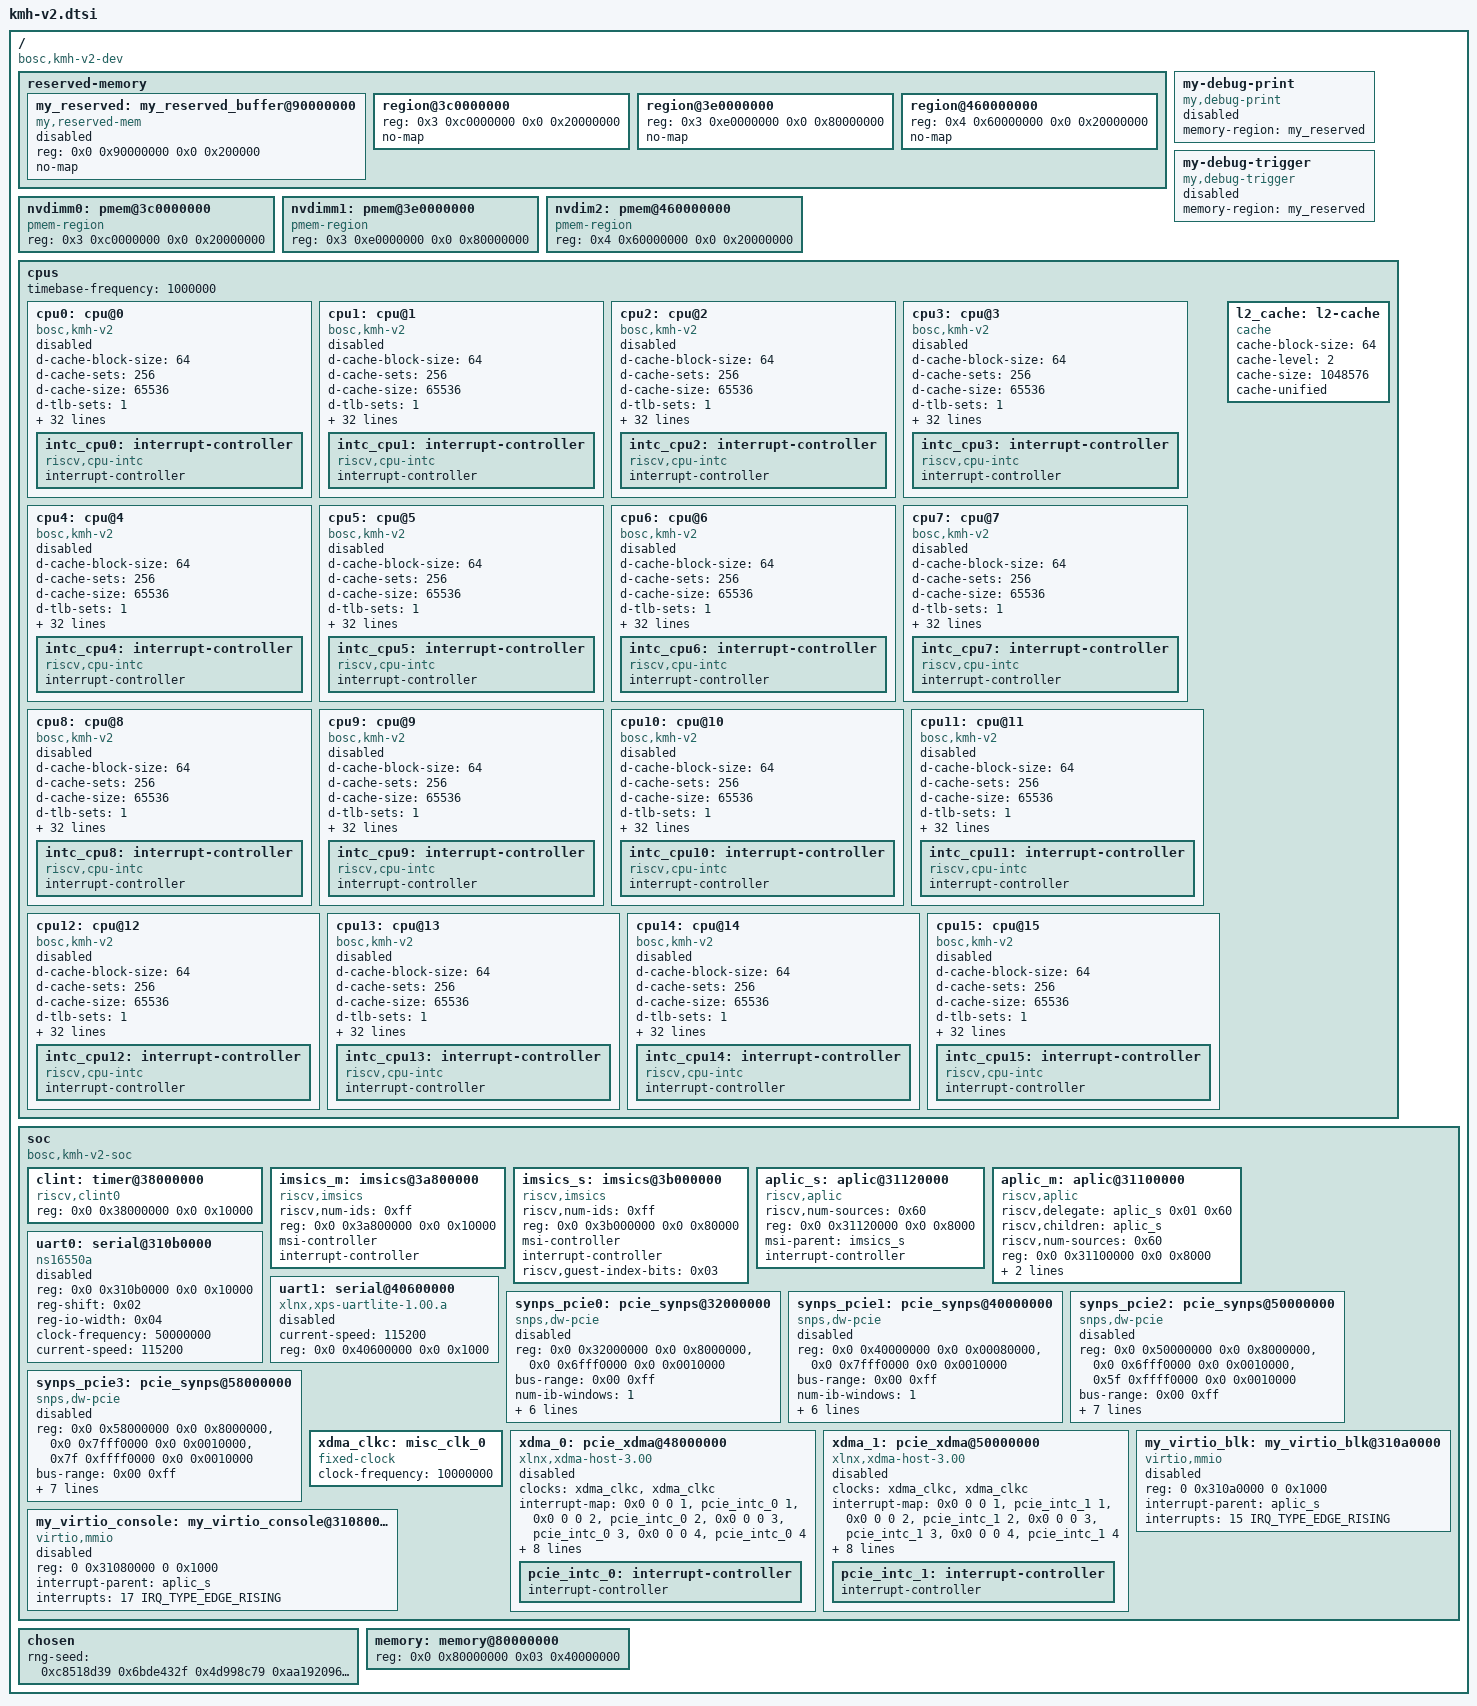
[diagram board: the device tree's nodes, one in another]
// SPDX-License-Identifier: (GPL-2.0 OR MIT)
/* Copyright (c) 2023-2024 BOSC */

/dts-v1/;
#include <dt-bindings/interrupt-controller/irq.h>
/ {
	compatible = "bosc,kmh-v2-dev";
	#address-cells = <2>;
	#size-cells = <2>;

	reserved-memory {
		#address-cells = <2>;
		#size-cells = <2>;
		ranges;

		my_reserved:my_reserved_buffer@90000000 {
			compatible = "my,reserved-mem";
			reg = <0x0 0x90000000 0x0 0x200000>;
			no-map;
			status = "disabled";
		};

		/*
		* NOTE: This region's 'reg' must exactly match the 'reg' in nvdimm_pmem node.
		*       Mismatch will cause pmem driver failure or memory conflict.
		*/
		region@3c0000000 {
		    reg = <0x3 0xc0000000 0x0 0x20000000>;  // 512MB
		    no-map;
		};
		region@3e0000000 {
		    reg = <0x3 0xe0000000 0x0 0x80000000>;  // 2GB
		    no-map;
		};
		region@460000000 {
		    reg = <0x4 0x60000000 0x0 0x20000000>;  // 512MB
		    no-map;
		};
	};

	my-debug-print {
		compatible = "my,debug-print";
		memory-region = <&my_reserved>;
		status = "disabled";
	};
	my-debug-trigger {
		compatible = "my,debug-trigger";
		memory-region = <&my_reserved>;
		status = "disabled";
	};

	nvdimm0: pmem@3c0000000 {
	    compatible = "pmem-region", "nvdimm";
	    reg = <0x3 0xc0000000 0x0 0x20000000>;  // 512MB
	    status = "okay";
	};

	nvdimm1: pmem@3e0000000 {
	    compatible = "pmem-region", "nvdimm";
	    reg = <0x3 0xe0000000 0x0 0x80000000>;  // 2GB
	    status = "okay";
	};

	nvdim2: pmem@460000000 {
	    compatible = "pmem-region", "nvdimm";
	    reg = <0x4 0x60000000 0x0 0x20000000>;  // 512MB
	    status = "okay";
	};

	cpus {
		#address-cells = <1>;
		#size-cells = <0>;
		timebase-frequency = <1000000>; /* 1Mhz */
//		has_hcontext;

		cpu0: cpu@0 {
			compatible = "bosc,kmh-v2", "riscv";
			d-cache-block-size = <64>;
			d-cache-sets = <256>;
			d-cache-size = <65536>;
			d-tlb-sets = <1>;
			d-tlb-size = <48>;
			device_type = "cpu";
			i-cache-block-size = <64>;
			i-cache-sets = <256>;
			i-cache-size = <65536>;
			i-tlb-sets = <1>;
			i-tlb-size = <48>;
			mmu-type = "riscv,sv48";
			reg = <0x0>;
			riscv,isa = "rv64imafdcvh_smaia_smstateen_sscofpmf_sstc_zicntr_zihpm_zicboz_zicbom_svpbmt_sdtrig_smcsrind_sscsrind_svade";
			riscv,isa-base = "rv64i";
			riscv,isa-extensions = "i", "m", "a", "f", "d", "c", "v", "h", "sdtrig", "sha", "shcounterenw", "shgatpa", "shlcofideleg", "shtvala", "shvsatpa", "shvstvala", "shvstvecd", "smaia", "smcsrind", "smdbltrp", "smmpm", "smnpm", "smrnmi", "smstateen", "ss1p13", "ssaia", "ssccptr", "sscofpmf", "sscounterenw", "sscsrind", "ssdbltrp", "ssnpm", "sspm", "ssstateen", "ssstrict", "sstc", "sstvala", "sstvecd", "ssu64xl", "supm", "sv39", "sv48", "svade", "svbare", "svinval", "svnapot", "svpbmt", "za64rs", "zacas", "zawrs", "zba", "zbb", "zbc", "zbkb", "zbkc", "zbkx", "zbs", "zcb", "zcmop", "zfa", "zfh", "zfhmin", "zic64b", "zicbom", "zicbop", "zicboz", "ziccamoa", "ziccif", "zicclsm", "ziccrse", "zicntr", "zicond", "zicsr", "zifencei", "zihintntl", "zihintpause", "zihpm", "zimop", "zkn", "zknd", "zkne", "zknh", "zksed", "zksh", "zkt", "zvbb", "zvfh", "zvfhmin", "zvkt", "zvl128b", "zvl32b", "zvl64b";
			riscv,cbom-block-size = <0x40>;
			riscv,cboz-block-size = <0x40>;
                        status = "disabled";

			next-level-cache = <&l2_cache>;
			tlb-split;
			intc_cpu0: interrupt-controller {
				#interrupt-cells = <1>;
				compatible = "riscv,cpu-intc";
				interrupt-controller;
			};
		};
		cpu1: cpu@1 {
			compatible = "bosc,kmh-v2", "riscv";
			d-cache-block-size = <64>;
			d-cache-sets = <256>;
			d-cache-size = <65536>;
			d-tlb-sets = <1>;
			d-tlb-size = <48>;
			device_type = "cpu";
			i-cache-block-size = <64>;
			i-cache-sets = <256>;
			i-cache-size = <65536>;
			i-tlb-sets = <1>;
			i-tlb-size = <48>;
			mmu-type = "riscv,sv48";
			reg = <0x1>;
			riscv,isa = "rv64imafdcvh_smaia_smstateen_sscofpmf_sstc_zicntr_zihpm_zicboz_zicbom_svpbmt_sdtrig_smcsrind_sscsrind_svade";
			riscv,isa-base = "rv64i";
			riscv,isa-extensions = "i", "m", "a", "f", "d", "c", "v", "h", "sdtrig", "sha", "shcounterenw", "shgatpa", "shlcofideleg", "shtvala", "shvsatpa", "shvstvala", "shvstvecd", "smaia", "smcsrind", "smdbltrp", "smmpm", "smnpm", "smrnmi", "smstateen", "ss1p13", "ssaia", "ssccptr", "sscofpmf", "sscounterenw", "sscsrind", "ssdbltrp", "ssnpm", "sspm", "ssstateen", "ssstrict", "sstc", "sstvala", "sstvecd", "ssu64xl", "supm", "sv39", "sv48", "svade", "svbare", "svinval", "svnapot", "svpbmt", "za64rs", "zacas", "zawrs", "zba", "zbb", "zbc", "zbkb", "zbkc", "zbkx", "zbs", "zcb", "zcmop", "zfa", "zfh", "zfhmin", "zic64b", "zicbom", "zicbop", "zicboz", "ziccamoa", "ziccif", "zicclsm", "ziccrse", "zicntr", "zicond", "zicsr", "zifencei", "zihintntl", "zihintpause", "zihpm", "zimop", "zkn", "zknd", "zkne", "zknh", "zksed", "zksh", "zkt", "zvbb", "zvfh", "zvfhmin", "zvkt", "zvl128b", "zvl32b", "zvl64b";
			riscv,cbom-block-size = <0x40>;
			riscv,cboz-block-size = <0x40>;
                        status = "disabled";

			next-level-cache = <&l2_cache>;
			tlb-split;
			intc_cpu1: interrupt-controller {
				#interrupt-cells = <1>;
				compatible = "riscv,cpu-intc";
				interrupt-controller;
			};
		};
		cpu2: cpu@2 {
			compatible = "bosc,kmh-v2", "riscv";
			d-cache-block-size = <64>;
			d-cache-sets = <256>;
			d-cache-size = <65536>;
			d-tlb-sets = <1>;
			d-tlb-size = <48>;
			device_type = "cpu";
			i-cache-block-size = <64>;
			i-cache-sets = <256>;
			i-cache-size = <65536>;
			i-tlb-sets = <1>;
			i-tlb-size = <48>;
			mmu-type = "riscv,sv48";
			reg = <0x2>;
			riscv,isa = "rv64imafdcvh_smaia_smstateen_sscofpmf_sstc_zicntr_zihpm_zicboz_zicbom_svpbmt_sdtrig_smcsrind_sscsrind_svade";
			riscv,isa-base = "rv64i";
			riscv,isa-extensions = "i", "m", "a", "f", "d", "c", "v", "h", "sdtrig", "sha", "shcounterenw", "shgatpa", "shlcofideleg", "shtvala", "shvsatpa", "shvstvala", "shvstvecd", "smaia", "smcsrind", "smdbltrp", "smmpm", "smnpm", "smrnmi", "smstateen", "ss1p13", "ssaia", "ssccptr", "sscofpmf", "sscounterenw", "sscsrind", "ssdbltrp", "ssnpm", "sspm", "ssstateen", "ssstrict", "sstc", "sstvala", "sstvecd", "ssu64xl", "supm", "sv39", "sv48", "svade", "svbare", "svinval", "svnapot", "svpbmt", "za64rs", "zacas", "zawrs", "zba", "zbb", "zbc", "zbkb", "zbkc", "zbkx", "zbs", "zcb", "zcmop", "zfa", "zfh", "zfhmin", "zic64b", "zicbom", "zicbop", "zicboz", "ziccamoa", "ziccif", "zicclsm", "ziccrse", "zicntr", "zicond", "zicsr", "zifencei", "zihintntl", "zihintpause", "zihpm", "zimop", "zkn", "zknd", "zkne", "zknh", "zksed", "zksh", "zkt", "zvbb", "zvfh", "zvfhmin", "zvkt", "zvl128b", "zvl32b", "zvl64b";
			riscv,cbom-block-size = <0x40>;
			riscv,cboz-block-size = <0x40>;
                        status = "disabled";

			next-level-cache = <&l2_cache>;
			tlb-split;
			intc_cpu2: interrupt-controller {
				#interrupt-cells = <1>;
				compatible = "riscv,cpu-intc";
				interrupt-controller;
			};
		};
		cpu3: cpu@3 {
			compatible = "bosc,kmh-v2", "riscv";
			d-cache-block-size = <64>;
			d-cache-sets = <256>;
			d-cache-size = <65536>;
			d-tlb-sets = <1>;
			d-tlb-size = <48>;
			device_type = "cpu";
			i-cache-block-size = <64>;
			i-cache-sets = <256>;
			i-cache-size = <65536>;
			i-tlb-sets = <1>;
			i-tlb-size = <48>;
			mmu-type = "riscv,sv48";
			reg = <0x3>;
			riscv,isa = "rv64imafdcvh_smaia_smstateen_sscofpmf_sstc_zicntr_zihpm_zicboz_zicbom_svpbmt_sdtrig_smcsrind_sscsrind_svade";
			riscv,isa-base = "rv64i";
			riscv,isa-extensions = "i", "m", "a", "f", "d", "c", "v", "h", "sdtrig", "sha", "shcounterenw", "shgatpa", "shlcofideleg", "shtvala", "shvsatpa", "shvstvala", "shvstvecd", "smaia", "smcsrind", "smdbltrp", "smmpm", "smnpm", "smrnmi", "smstateen", "ss1p13", "ssaia", "ssccptr", "sscofpmf", "sscounterenw", "sscsrind", "ssdbltrp", "ssnpm", "sspm", "ssstateen", "ssstrict", "sstc", "sstvala", "sstvecd", "ssu64xl", "supm", "sv39", "sv48", "svade", "svbare", "svinval", "svnapot", "svpbmt", "za64rs", "zacas", "zawrs", "zba", "zbb", "zbc", "zbkb", "zbkc", "zbkx", "zbs", "zcb", "zcmop", "zfa", "zfh", "zfhmin", "zic64b", "zicbom", "zicbop", "zicboz", "ziccamoa", "ziccif", "zicclsm", "ziccrse", "zicntr", "zicond", "zicsr", "zifencei", "zihintntl", "zihintpause", "zihpm", "zimop", "zkn", "zknd", "zkne", "zknh", "zksed", "zksh", "zkt", "zvbb", "zvfh", "zvfhmin", "zvkt", "zvl128b", "zvl32b", "zvl64b";
			riscv,cbom-block-size = <0x40>;
			riscv,cboz-block-size = <0x40>;
                        status = "disabled";

			next-level-cache = <&l2_cache>;
			tlb-split;
			intc_cpu3: interrupt-controller {
				#interrupt-cells = <1>;
				compatible = "riscv,cpu-intc";
				interrupt-controller;
			};
		};
		cpu4: cpu@4 {
			compatible = "bosc,kmh-v2", "riscv";
			d-cache-block-size = <64>;
			d-cache-sets = <256>;
			d-cache-size = <65536>;
			d-tlb-sets = <1>;
			d-tlb-size = <48>;
			device_type = "cpu";
			i-cache-block-size = <64>;
			i-cache-sets = <256>;
			i-cache-size = <65536>;
			i-tlb-sets = <1>;
			i-tlb-size = <48>;
			mmu-type = "riscv,sv48";
			reg = <0x4>;
			riscv,isa = "rv64imafdcvh_smaia_smstateen_sscofpmf_sstc_zicntr_zihpm_zicboz_zicbom_svpbmt_sdtrig_smcsrind_sscsrind_svade";
			riscv,isa-base = "rv64i";
			riscv,isa-extensions = "i", "m", "a", "f", "d", "c", "v", "h", "sdtrig", "sha", "shcounterenw", "shgatpa", "shlcofideleg", "shtvala", "shvsatpa", "shvstvala", "shvstvecd", "smaia", "smcsrind", "smdbltrp", "smmpm", "smnpm", "smrnmi", "smstateen", "ss1p13", "ssaia", "ssccptr", "sscofpmf", "sscounterenw", "sscsrind", "ssdbltrp", "ssnpm", "sspm", "ssstateen", "ssstrict", "sstc", "sstvala", "sstvecd", "ssu64xl", "supm", "sv39", "sv48", "svade", "svbare", "svinval", "svnapot", "svpbmt", "za64rs", "zacas", "zawrs", "zba", "zbb", "zbc", "zbkb", "zbkc", "zbkx", "zbs", "zcb", "zcmop", "zfa", "zfh", "zfhmin", "zic64b", "zicbom", "zicbop", "zicboz", "ziccamoa", "ziccif", "zicclsm", "ziccrse", "zicntr", "zicond", "zicsr", "zifencei", "zihintntl", "zihintpause", "zihpm", "zimop", "zkn", "zknd", "zkne", "zknh", "zksed", "zksh", "zkt", "zvbb", "zvfh", "zvfhmin", "zvkt", "zvl128b", "zvl32b", "zvl64b";
			riscv,cbom-block-size = <0x40>;
			riscv,cboz-block-size = <0x40>;
                        status = "disabled";

			next-level-cache = <&l2_cache>;
			tlb-split;
			intc_cpu4: interrupt-controller {
				#interrupt-cells = <1>;
				compatible = "riscv,cpu-intc";
				interrupt-controller;
			};
		};
		cpu5: cpu@5 {
			compatible = "bosc,kmh-v2", "riscv";
			d-cache-block-size = <64>;
			d-cache-sets = <256>;
			d-cache-size = <65536>;
			d-tlb-sets = <1>;
			d-tlb-size = <48>;
			device_type = "cpu";
			i-cache-block-size = <64>;
			i-cache-sets = <256>;
			i-cache-size = <65536>;
			i-tlb-sets = <1>;
			i-tlb-size = <48>;
			mmu-type = "riscv,sv48";
			reg = <0x5>;
			riscv,isa = "rv64imafdcvh_smaia_smstateen_sscofpmf_sstc_zicntr_zihpm_zicboz_zicbom_svpbmt_sdtrig_smcsrind_sscsrind_svade";
			riscv,isa-base = "rv64i";
			riscv,isa-extensions = "i", "m", "a", "f", "d", "c", "v", "h", "sdtrig", "sha", "shcounterenw", "shgatpa", "shlcofideleg", "shtvala", "shvsatpa", "shvstvala", "shvstvecd", "smaia", "smcsrind", "smdbltrp", "smmpm", "smnpm", "smrnmi", "smstateen", "ss1p13", "ssaia", "ssccptr", "sscofpmf", "sscounterenw", "sscsrind", "ssdbltrp", "ssnpm", "sspm", "ssstateen", "ssstrict", "sstc", "sstvala", "sstvecd", "ssu64xl", "supm", "sv39", "sv48", "svade", "svbare", "svinval", "svnapot", "svpbmt", "za64rs", "zacas", "zawrs", "zba", "zbb", "zbc", "zbkb", "zbkc", "zbkx", "zbs", "zcb", "zcmop", "zfa", "zfh", "zfhmin", "zic64b", "zicbom", "zicbop", "zicboz", "ziccamoa", "ziccif", "zicclsm", "ziccrse", "zicntr", "zicond", "zicsr", "zifencei", "zihintntl", "zihintpause", "zihpm", "zimop", "zkn", "zknd", "zkne", "zknh", "zksed", "zksh", "zkt", "zvbb", "zvfh", "zvfhmin", "zvkt", "zvl128b", "zvl32b", "zvl64b";
			riscv,cbom-block-size = <0x40>;
			riscv,cboz-block-size = <0x40>;
                        status = "disabled";

			next-level-cache = <&l2_cache>;
			tlb-split;
			intc_cpu5: interrupt-controller {
				#interrupt-cells = <1>;
				compatible = "riscv,cpu-intc";
				interrupt-controller;
			};
		};
		cpu6: cpu@6 {
			compatible = "bosc,kmh-v2", "riscv";
			d-cache-block-size = <64>;
			d-cache-sets = <256>;
			d-cache-size = <65536>;
			d-tlb-sets = <1>;
			d-tlb-size = <48>;
			device_type = "cpu";
			i-cache-block-size = <64>;
			i-cache-sets = <256>;
			i-cache-size = <65536>;
			i-tlb-sets = <1>;
			i-tlb-size = <48>;
			mmu-type = "riscv,sv48";
			reg = <0x6>;
			riscv,isa = "rv64imafdcvh_smaia_smstateen_sscofpmf_sstc_zicntr_zihpm_zicboz_zicbom_svpbmt_sdtrig_smcsrind_sscsrind_svade";
			riscv,isa-base = "rv64i";
			riscv,isa-extensions = "i", "m", "a", "f", "d", "c", "v", "h", "sdtrig", "sha", "shcounterenw", "shgatpa", "shlcofideleg", "shtvala", "shvsatpa", "shvstvala", "shvstvecd", "smaia", "smcsrind", "smdbltrp", "smmpm", "smnpm", "smrnmi", "smstateen", "ss1p13", "ssaia", "ssccptr", "sscofpmf", "sscounterenw", "sscsrind", "ssdbltrp", "ssnpm", "sspm", "ssstateen", "ssstrict", "sstc", "sstvala", "sstvecd", "ssu64xl", "supm", "sv39", "sv48", "svade", "svbare", "svinval", "svnapot", "svpbmt", "za64rs", "zacas", "zawrs", "zba", "zbb", "zbc", "zbkb", "zbkc", "zbkx", "zbs", "zcb", "zcmop", "zfa", "zfh", "zfhmin", "zic64b", "zicbom", "zicbop", "zicboz", "ziccamoa", "ziccif", "zicclsm", "ziccrse", "zicntr", "zicond", "zicsr", "zifencei", "zihintntl", "zihintpause", "zihpm", "zimop", "zkn", "zknd", "zkne", "zknh", "zksed", "zksh", "zkt", "zvbb", "zvfh", "zvfhmin", "zvkt", "zvl128b", "zvl32b", "zvl64b";
			riscv,cbom-block-size = <0x40>;
			riscv,cboz-block-size = <0x40>;
                        status = "disabled";

			next-level-cache = <&l2_cache>;
			tlb-split;
			intc_cpu6: interrupt-controller {
				#interrupt-cells = <1>;
				compatible = "riscv,cpu-intc";
				interrupt-controller;
			};
		};
		cpu7: cpu@7 {
			compatible = "bosc,kmh-v2", "riscv";
			d-cache-block-size = <64>;
			d-cache-sets = <256>;
			d-cache-size = <65536>;
			d-tlb-sets = <1>;
			d-tlb-size = <48>;
			device_type = "cpu";
			i-cache-block-size = <64>;
			i-cache-sets = <256>;
			i-cache-size = <65536>;
			i-tlb-sets = <1>;
			i-tlb-size = <48>;
			mmu-type = "riscv,sv48";
			reg = <0x7>;
			riscv,isa = "rv64imafdcvh_smaia_smstateen_sscofpmf_sstc_zicntr_zihpm_zicboz_zicbom_svpbmt_sdtrig_smcsrind_sscsrind_svade";
			riscv,isa-base = "rv64i";
			riscv,isa-extensions = "i", "m", "a", "f", "d", "c", "v", "h", "sdtrig", "sha", "shcounterenw", "shgatpa", "shlcofideleg", "shtvala", "shvsatpa", "shvstvala", "shvstvecd", "smaia", "smcsrind", "smdbltrp", "smmpm", "smnpm", "smrnmi", "smstateen", "ss1p13", "ssaia", "ssccptr", "sscofpmf", "sscounterenw", "sscsrind", "ssdbltrp", "ssnpm", "sspm", "ssstateen", "ssstrict", "sstc", "sstvala", "sstvecd", "ssu64xl", "supm", "sv39", "sv48", "svade", "svbare", "svinval", "svnapot", "svpbmt", "za64rs", "zacas", "zawrs", "zba", "zbb", "zbc", "zbkb", "zbkc", "zbkx", "zbs", "zcb", "zcmop", "zfa", "zfh", "zfhmin", "zic64b", "zicbom", "zicbop", "zicboz", "ziccamoa", "ziccif", "zicclsm", "ziccrse", "zicntr", "zicond", "zicsr", "zifencei", "zihintntl", "zihintpause", "zihpm", "zimop", "zkn", "zknd", "zkne", "zknh", "zksed", "zksh", "zkt", "zvbb", "zvfh", "zvfhmin", "zvkt", "zvl128b", "zvl32b", "zvl64b";
			riscv,cbom-block-size = <0x40>;
			riscv,cboz-block-size = <0x40>;
                        status = "disabled";

			next-level-cache = <&l2_cache>;
			tlb-split;
			intc_cpu7: interrupt-controller {
				#interrupt-cells = <1>;
				compatible = "riscv,cpu-intc";
				interrupt-controller;
			};
		};
		cpu8: cpu@8 {
			compatible = "bosc,kmh-v2", "riscv";
			d-cache-block-size = <64>;
			d-cache-sets = <256>;
			d-cache-size = <65536>;
			d-tlb-sets = <1>;
			d-tlb-size = <48>;
			device_type = "cpu";
			i-cache-block-size = <64>;
			i-cache-sets = <256>;
			i-cache-size = <65536>;
			i-tlb-sets = <1>;
			i-tlb-size = <48>;
			mmu-type = "riscv,sv48";
			reg = <0x8>;
			riscv,isa = "rv64imafdcvh_smaia_smstateen_sscofpmf_sstc_zicntr_zihpm_zicboz_zicbom_svpbmt_sdtrig_smcsrind_sscsrind_svade";
			riscv,isa-base = "rv64i";
			riscv,isa-extensions = "i", "m", "a", "f", "d", "c", "v", "h", "sdtrig", "sha", "shcounterenw", "shgatpa", "shlcofideleg", "shtvala", "shvsatpa", "shvstvala", "shvstvecd", "smaia", "smcsrind", "smdbltrp", "smmpm", "smnpm", "smrnmi", "smstateen", "ss1p13", "ssaia", "ssccptr", "sscofpmf", "sscounterenw", "sscsrind", "ssdbltrp", "ssnpm", "sspm", "ssstateen", "ssstrict", "sstc", "sstvala", "sstvecd", "ssu64xl", "supm", "sv39", "sv48", "svade", "svbare", "svinval", "svnapot", "svpbmt", "za64rs", "zacas", "zawrs", "zba", "zbb", "zbc", "zbkb", "zbkc", "zbkx", "zbs", "zcb", "zcmop", "zfa", "zfh", "zfhmin", "zic64b", "zicbom", "zicbop", "zicboz", "ziccamoa", "ziccif", "zicclsm", "ziccrse", "zicntr", "zicond", "zicsr", "zifencei", "zihintntl", "zihintpause", "zihpm", "zimop", "zkn", "zknd", "zkne", "zknh", "zksed", "zksh", "zkt", "zvbb", "zvfh", "zvfhmin", "zvkt", "zvl128b", "zvl32b", "zvl64b";
			riscv,cbom-block-size = <0x40>;
			riscv,cboz-block-size = <0x40>;
                        status = "disabled";

			next-level-cache = <&l2_cache>;
			tlb-split;
			intc_cpu8: interrupt-controller {
				#interrupt-cells = <1>;
				compatible = "riscv,cpu-intc";
				interrupt-controller;
			};
		};
		cpu9: cpu@9 {
			compatible = "bosc,kmh-v2", "riscv";
			d-cache-block-size = <64>;
			d-cache-sets = <256>;
			d-cache-size = <65536>;
			d-tlb-sets = <1>;
			d-tlb-size = <48>;
			device_type = "cpu";
			i-cache-block-size = <64>;
			i-cache-sets = <256>;
			i-cache-size = <65536>;
			i-tlb-sets = <1>;
			i-tlb-size = <48>;
			mmu-type = "riscv,sv48";
			reg = <0x9>;
			riscv,isa = "rv64imafdcvh_smaia_smstateen_sscofpmf_sstc_zicntr_zihpm_zicboz_zicbom_svpbmt_sdtrig_smcsrind_sscsrind_svade";
			riscv,isa-base = "rv64i";
			riscv,isa-extensions = "i", "m", "a", "f", "d", "c", "v", "h", "sdtrig", "sha", "shcounterenw", "shgatpa", "shlcofideleg", "shtvala", "shvsatpa", "shvstvala", "shvstvecd", "smaia", "smcsrind", "smdbltrp", "smmpm", "smnpm", "smrnmi", "smstateen", "ss1p13", "ssaia", "ssccptr", "sscofpmf", "sscounterenw", "sscsrind", "ssdbltrp", "ssnpm", "sspm", "ssstateen", "ssstrict", "sstc", "sstvala", "sstvecd", "ssu64xl", "supm", "sv39", "sv48", "svade", "svbare", "svinval", "svnapot", "svpbmt", "za64rs", "zacas", "zawrs", "zba", "zbb", "zbc", "zbkb", "zbkc", "zbkx", "zbs", "zcb", "zcmop", "zfa", "zfh", "zfhmin", "zic64b", "zicbom", "zicbop", "zicboz", "ziccamoa", "ziccif", "zicclsm", "ziccrse", "zicntr", "zicond", "zicsr", "zifencei", "zihintntl", "zihintpause", "zihpm", "zimop", "zkn", "zknd", "zkne", "zknh", "zksed", "zksh", "zkt", "zvbb", "zvfh", "zvfhmin", "zvkt", "zvl128b", "zvl32b", "zvl64b";
			riscv,cbom-block-size = <0x40>;
			riscv,cboz-block-size = <0x40>;
                        status = "disabled";

			next-level-cache = <&l2_cache>;
			tlb-split;
			intc_cpu9: interrupt-controller {
				#interrupt-cells = <1>;
				compatible = "riscv,cpu-intc";
				interrupt-controller;
			};
		};
		cpu10: cpu@10 {
			compatible = "bosc,kmh-v2", "riscv";
			d-cache-block-size = <64>;
			d-cache-sets = <256>;
			d-cache-size = <65536>;
			d-tlb-sets = <1>;
			d-tlb-size = <48>;
			device_type = "cpu";
			i-cache-block-size = <64>;
			i-cache-sets = <256>;
			i-cache-size = <65536>;
			i-tlb-sets = <1>;
			i-tlb-size = <48>;
			mmu-type = "riscv,sv48";
			reg = <0xa>;
			riscv,isa = "rv64imafdcvh_smaia_smstateen_sscofpmf_sstc_zicntr_zihpm_zicboz_zicbom_svpbmt_sdtrig_smcsrind_sscsrind_svade";
			riscv,isa-base = "rv64i";
			riscv,isa-extensions = "i", "m", "a", "f", "d", "c", "v", "h", "sdtrig", "sha", "shcounterenw", "shgatpa", "shlcofideleg", "shtvala", "shvsatpa", "shvstvala", "shvstvecd", "smaia", "smcsrind", "smdbltrp", "smmpm", "smnpm", "smrnmi", "smstateen", "ss1p13", "ssaia", "ssccptr", "sscofpmf", "sscounterenw", "sscsrind", "ssdbltrp", "ssnpm", "sspm", "ssstateen", "ssstrict", "sstc", "sstvala", "sstvecd", "ssu64xl", "supm", "sv39", "sv48", "svade", "svbare", "svinval", "svnapot", "svpbmt", "za64rs", "zacas", "zawrs", "zba", "zbb", "zbc", "zbkb", "zbkc", "zbkx", "zbs", "zcb", "zcmop", "zfa", "zfh", "zfhmin", "zic64b", "zicbom", "zicbop", "zicboz", "ziccamoa", "ziccif", "zicclsm", "ziccrse", "zicntr", "zicond", "zicsr", "zifencei", "zihintntl", "zihintpause", "zihpm", "zimop", "zkn", "zknd", "zkne", "zknh", "zksed", "zksh", "zkt", "zvbb", "zvfh", "zvfhmin", "zvkt", "zvl128b", "zvl32b", "zvl64b";
			riscv,cbom-block-size = <0x40>;
			riscv,cboz-block-size = <0x40>;
                        status = "disabled";

			next-level-cache = <&l2_cache>;
			tlb-split;
			intc_cpu10: interrupt-controller {
				#interrupt-cells = <1>;
				compatible = "riscv,cpu-intc";
				interrupt-controller;
			};
		};
		cpu11: cpu@11 {
			compatible = "bosc,kmh-v2", "riscv";
			d-cache-block-size = <64>;
			d-cache-sets = <256>;
			d-cache-size = <65536>;
			d-tlb-sets = <1>;
			d-tlb-size = <48>;
			device_type = "cpu";
			i-cache-block-size = <64>;
			i-cache-sets = <256>;
			i-cache-size = <65536>;
			i-tlb-sets = <1>;
			i-tlb-size = <48>;
			mmu-type = "riscv,sv48";
			reg = <0xb>;
			riscv,isa = "rv64imafdcvh_smaia_smstateen_sscofpmf_sstc_zicntr_zihpm_zicboz_zicbom_svpbmt_sdtrig_smcsrind_sscsrind_svade";
			riscv,isa-base = "rv64i";
			riscv,isa-extensions = "i", "m", "a", "f", "d", "c", "v", "h", "sdtrig", "sha", "shcounterenw", "shgatpa", "shlcofideleg", "shtvala", "shvsatpa", "shvstvala", "shvstvecd", "smaia", "smcsrind", "smdbltrp", "smmpm", "smnpm", "smrnmi", "smstateen", "ss1p13", "ssaia", "ssccptr", "sscofpmf", "sscounterenw", "sscsrind", "ssdbltrp", "ssnpm", "sspm", "ssstateen", "ssstrict", "sstc", "sstvala", "sstvecd", "ssu64xl", "supm", "sv39", "sv48", "svade", "svbare", "svinval", "svnapot", "svpbmt", "za64rs", "zacas", "zawrs", "zba", "zbb", "zbc", "zbkb", "zbkc", "zbkx", "zbs", "zcb", "zcmop", "zfa", "zfh", "zfhmin", "zic64b", "zicbom", "zicbop", "zicboz", "ziccamoa", "ziccif", "zicclsm", "ziccrse", "zicntr", "zicond", "zicsr", "zifencei", "zihintntl", "zihintpause", "zihpm", "zimop", "zkn", "zknd", "zkne", "zknh", "zksed", "zksh", "zkt", "zvbb", "zvfh", "zvfhmin", "zvkt", "zvl128b", "zvl32b", "zvl64b";
			riscv,cbom-block-size = <0x40>;
			riscv,cboz-block-size = <0x40>;
                        status = "disabled";

			next-level-cache = <&l2_cache>;
			tlb-split;
			intc_cpu11: interrupt-controller {
				#interrupt-cells = <1>;
				compatible = "riscv,cpu-intc";
				interrupt-controller;
			};
		};
		cpu12: cpu@12 {
			compatible = "bosc,kmh-v2", "riscv";
			d-cache-block-size = <64>;
			d-cache-sets = <256>;
			d-cache-size = <65536>;
			d-tlb-sets = <1>;
			d-tlb-size = <48>;
			device_type = "cpu";
			i-cache-block-size = <64>;
			i-cache-sets = <256>;
			i-cache-size = <65536>;
			i-tlb-sets = <1>;
			i-tlb-size = <48>;
			mmu-type = "riscv,sv48";
			reg = <0xc>;
			riscv,isa = "rv64imafdcvh_smaia_smstateen_sscofpmf_sstc_zicntr_zihpm_zicboz_zicbom_svpbmt_sdtrig_smcsrind_sscsrind_svade";
			riscv,isa-base = "rv64i";
			riscv,isa-extensions = "i", "m", "a", "f", "d", "c", "v", "h", "sdtrig", "sha", "shcounterenw", "shgatpa", "shlcofideleg", "shtvala", "shvsatpa", "shvstvala", "shvstvecd", "smaia", "smcsrind", "smdbltrp", "smmpm", "smnpm", "smrnmi", "smstateen", "ss1p13", "ssaia", "ssccptr", "sscofpmf", "sscounterenw", "sscsrind", "ssdbltrp", "ssnpm", "sspm", "ssstateen", "ssstrict", "sstc", "sstvala", "sstvecd", "ssu64xl", "supm", "sv39", "sv48", "svade", "svbare", "svinval", "svnapot", "svpbmt", "za64rs", "zacas", "zawrs", "zba", "zbb", "zbc", "zbkb", "zbkc", "zbkx", "zbs", "zcb", "zcmop", "zfa", "zfh", "zfhmin", "zic64b", "zicbom", "zicbop", "zicboz", "ziccamoa", "ziccif", "zicclsm", "ziccrse", "zicntr", "zicond", "zicsr", "zifencei", "zihintntl", "zihintpause", "zihpm", "zimop", "zkn", "zknd", "zkne", "zknh", "zksed", "zksh", "zkt", "zvbb", "zvfh", "zvfhmin", "zvkt", "zvl128b", "zvl32b", "zvl64b";
			riscv,cbom-block-size = <0x40>;
			riscv,cboz-block-size = <0x40>;
                        status = "disabled";

			next-level-cache = <&l2_cache>;
			tlb-split;
			intc_cpu12: interrupt-controller {
				#interrupt-cells = <1>;
				compatible = "riscv,cpu-intc";
				interrupt-controller;
			};
		};
		cpu13: cpu@13 {
			compatible = "bosc,kmh-v2", "riscv";
			d-cache-block-size = <64>;
			d-cache-sets = <256>;
			d-cache-size = <65536>;
			d-tlb-sets = <1>;
			d-tlb-size = <48>;
			device_type = "cpu";
			i-cache-block-size = <64>;
			i-cache-sets = <256>;
			i-cache-size = <65536>;
			i-tlb-sets = <1>;
			i-tlb-size = <48>;
			mmu-type = "riscv,sv48";
			reg = <0xd>;
			riscv,isa = "rv64imafdcvh_smaia_smstateen_sscofpmf_sstc_zicntr_zihpm_zicboz_zicbom_svpbmt_sdtrig_smcsrind_sscsrind_svade";
			riscv,isa-base = "rv64i";
			riscv,isa-extensions = "i", "m", "a", "f", "d", "c", "v", "h", "sdtrig", "sha", "shcounterenw", "shgatpa", "shlcofideleg", "shtvala", "shvsatpa", "shvstvala", "shvstvecd", "smaia", "smcsrind", "smdbltrp", "smmpm", "smnpm", "smrnmi", "smstateen", "ss1p13", "ssaia", "ssccptr", "sscofpmf", "sscounterenw", "sscsrind", "ssdbltrp", "ssnpm", "sspm", "ssstateen", "ssstrict", "sstc", "sstvala", "sstvecd", "ssu64xl", "supm", "sv39", "sv48", "svade", "svbare", "svinval", "svnapot", "svpbmt", "za64rs", "zacas", "zawrs", "zba", "zbb", "zbc", "zbkb", "zbkc", "zbkx", "zbs", "zcb", "zcmop", "zfa", "zfh", "zfhmin", "zic64b", "zicbom", "zicbop", "zicboz", "ziccamoa", "ziccif", "zicclsm", "ziccrse", "zicntr", "zicond", "zicsr", "zifencei", "zihintntl", "zihintpause", "zihpm", "zimop", "zkn", "zknd", "zkne", "zknh", "zksed", "zksh", "zkt", "zvbb", "zvfh", "zvfhmin", "zvkt", "zvl128b", "zvl32b", "zvl64b";
			riscv,cbom-block-size = <0x40>;
			riscv,cboz-block-size = <0x40>;
                        status = "disabled";

			next-level-cache = <&l2_cache>;
			tlb-split;
			intc_cpu13: interrupt-controller {
				#interrupt-cells = <1>;
				compatible = "riscv,cpu-intc";
				interrupt-controller;
			};
		};
		cpu14: cpu@14 {
			compatible = "bosc,kmh-v2", "riscv";
			d-cache-block-size = <64>;
			d-cache-sets = <256>;
			d-cache-size = <65536>;
			d-tlb-sets = <1>;
			d-tlb-size = <48>;
			device_type = "cpu";
			i-cache-block-size = <64>;
			i-cache-sets = <256>;
			i-cache-size = <65536>;
			i-tlb-sets = <1>;
			i-tlb-size = <48>;
			mmu-type = "riscv,sv48";
			reg = <0xe>;
			riscv,isa = "rv64imafdcvh_smaia_smstateen_sscofpmf_sstc_zicntr_zihpm_zicboz_zicbom_svpbmt_sdtrig_smcsrind_sscsrind_svade";
			riscv,isa-base = "rv64i";
			riscv,isa-extensions = "i", "m", "a", "f", "d", "c", "v", "h", "sdtrig", "sha", "shcounterenw", "shgatpa", "shlcofideleg", "shtvala", "shvsatpa", "shvstvala", "shvstvecd", "smaia", "smcsrind", "smdbltrp", "smmpm", "smnpm", "smrnmi", "smstateen", "ss1p13", "ssaia", "ssccptr", "sscofpmf", "sscounterenw", "sscsrind", "ssdbltrp", "ssnpm", "sspm", "ssstateen", "ssstrict", "sstc", "sstvala", "sstvecd", "ssu64xl", "supm", "sv39", "sv48", "svade", "svbare", "svinval", "svnapot", "svpbmt", "za64rs", "zacas", "zawrs", "zba", "zbb", "zbc", "zbkb", "zbkc", "zbkx", "zbs", "zcb", "zcmop", "zfa", "zfh", "zfhmin", "zic64b", "zicbom", "zicbop", "zicboz", "ziccamoa", "ziccif", "zicclsm", "ziccrse", "zicntr", "zicond", "zicsr", "zifencei", "zihintntl", "zihintpause", "zihpm", "zimop", "zkn", "zknd", "zkne", "zknh", "zksed", "zksh", "zkt", "zvbb", "zvfh", "zvfhmin", "zvkt", "zvl128b", "zvl32b", "zvl64b";
			riscv,cbom-block-size = <0x40>;
			riscv,cboz-block-size = <0x40>;
                        status = "disabled";

			next-level-cache = <&l2_cache>;
			tlb-split;
			intc_cpu14: interrupt-controller {
				#interrupt-cells = <1>;
				compatible = "riscv,cpu-intc";
				interrupt-controller;
			};
		};
		cpu15: cpu@15 {
			compatible = "bosc,kmh-v2", "riscv";
			d-cache-block-size = <64>;
			d-cache-sets = <256>;
			d-cache-size = <65536>;
			d-tlb-sets = <1>;
			d-tlb-size = <48>;
			device_type = "cpu";
			i-cache-block-size = <64>;
			i-cache-sets = <256>;
			i-cache-size = <65536>;
			i-tlb-sets = <1>;
			i-tlb-size = <48>;
			mmu-type = "riscv,sv48";
			reg = <0xf>;
			riscv,isa = "rv64imafdcvh_smaia_smstateen_sscofpmf_sstc_zicntr_zihpm_zicboz_zicbom_svpbmt_sdtrig_smcsrind_sscsrind_svade";
			riscv,isa-base = "rv64i";
			riscv,isa-extensions = "i", "m", "a", "f", "d", "c", "v", "h", "sdtrig", "sha", "shcounterenw", "shgatpa", "shlcofideleg", "shtvala", "shvsatpa", "shvstvala", "shvstvecd", "smaia", "smcsrind", "smdbltrp", "smmpm", "smnpm", "smrnmi", "smstateen", "ss1p13", "ssaia", "ssccptr", "sscofpmf", "sscounterenw", "sscsrind", "ssdbltrp", "ssnpm", "sspm", "ssstateen", "ssstrict", "sstc", "sstvala", "sstvecd", "ssu64xl", "supm", "sv39", "sv48", "svade", "svbare", "svinval", "svnapot", "svpbmt", "za64rs", "zacas", "zawrs", "zba", "zbb", "zbc", "zbkb", "zbkc", "zbkx", "zbs", "zcb", "zcmop", "zfa", "zfh", "zfhmin", "zic64b", "zicbom", "zicbop", "zicboz", "ziccamoa", "ziccif", "zicclsm", "ziccrse", "zicntr", "zicond", "zicsr", "zifencei", "zihintntl", "zihintpause", "zihpm", "zimop", "zkn", "zknd", "zkne", "zknh", "zksed", "zksh", "zkt", "zvbb", "zvfh", "zvfhmin", "zvkt", "zvl128b", "zvl32b", "zvl64b";
			riscv,cbom-block-size = <0x40>;
			riscv,cboz-block-size = <0x40>;
                        status = "disabled";

			next-level-cache = <&l2_cache>;
			tlb-split;
			intc_cpu15: interrupt-controller {
				#interrupt-cells = <1>;
				compatible = "riscv,cpu-intc";
				interrupt-controller;
			};
		};

		l2_cache: l2-cache {
			compatible = "cache";
			cache-block-size = <64>;
			cache-level = <2>;
			cache-size = <1048576>; /* 1MiB */
			cache-unified;
		};
	};

	soc {
		#address-cells = <2>;
		#size-cells = <2>;
		compatible = "bosc,kmh-v2-soc", "simple-bus";
		ranges;

		clint: timer@38000000 {
			compatible = "riscv,clint0";
			reg = <0x0 0x38000000 0x0 0x10000>;
		};

		imsics_m: imsics@3a800000 {
			riscv,num-ids = <0xff>;
			reg = <0x0 0x3a800000 0x0 0x10000>;
			msi-controller;
			interrupt-controller;
			#interrupt-cells = <0x00>;
			compatible = "riscv,imsics";
		};

		imsics_s: imsics@3b000000 {
			riscv,num-ids = <0xff>;
			reg = <0x0 0x3b000000 0x0 0x80000>;
			msi-controller;
			interrupt-controller;
			#interrupt-cells = <0x00>;
			compatible = "riscv,imsics";
			riscv,guest-index-bits = <0x03>;
		};

		aplic_s: aplic@31120000 {
			riscv,num-sources = <0x60>;
			reg = <0x0 0x31120000 0x0 0x8000>;
			msi-parent = <&imsics_s>;
			interrupt-controller;
			#interrupt-cells = <0x02>;
			compatible = "riscv,aplic";
		};

		aplic_m: aplic@31100000 {
			riscv,delegate = <&aplic_s 0x01 0x60>;
			riscv,children = <&aplic_s>;
			riscv,num-sources = <0x60>;
			reg = <0x0 0x31100000 0x0 0x8000>;
			msi-parent = <&imsics_m>;
			interrupt-controller;
			#interrupt-cells = <0x02>;
			compatible = "riscv,aplic";
		};

		uart0: serial@310b0000 {
			compatible = "ns16550a";
			reg = <0x0 0x310b0000 0x0 0x10000>;
			reg-shift = <0x02>;
			reg-io-width = <0x04>;
			clock-frequency = <50000000>;
			current-speed = <115200>;
			status = "disabled";
		};

		uart1: serial@40600000 {
			compatible = "xlnx,xps-uartlite-1.00.a";
			current-speed = <115200>;
			reg = <0x0 0x40600000 0x0 0x1000>;
			reg-names = "control";
			status = "disabled";
		};

		synps_pcie0: pcie_synps@32000000 {
			compatible = "snps,dw-pcie";
			reg = <0x0 0x32000000 0x0 0x8000000>,
				<0x0 0x6fff0000 0x0 0x0010000>;
			reg-names = "dbi", "config";
			#address-cells = <3>;
			#size-cells = <2>;
			device_type = "pci";
			bus-range = <0x00 0xff>;
			ranges = <0x02000000 0x00000000 0x40000000 0x00000000 0x60000000 0x00000000 0xfff0000>,
				 <0x03000000 0x00000040 0x00000000 0x00000040 0x00000000 0x00000002 0x0000000>;

			num-ib-windows = <1>;

			#interrupt-cells = <1>;
			interrupt-map-mask = <0x0 0 0 7>;

			interrupt-parent = <&aplic_s>;
			msi-parent = <&imsics_s>;
			interrupts = <12 IRQ_TYPE_EDGE_RISING>, <13 IRQ_TYPE_EDGE_RISING>;
			interrupt-names = "msi", "hp";
			num-lanes = <1>;
			status = "disabled";
		};
		synps_pcie1: pcie_synps@40000000 {
			compatible = "snps,dw-pcie";
			reg = <0x0 0x40000000 0x0 0x00080000>,
			      <0x0 0x7fff0000 0x0 0x0010000>;
			reg-names = "dbi", "config";
			#address-cells = <3>;
			#size-cells = <2>;
			device_type = "pci";
			bus-range = <0x00 0xff>;
			ranges = <0x02000000 0x00000000 0x40000000 0x00000000 0x70000000 0x00000000 0xfff0000>,
				 <0x03000000 0x00000060 0x00000000 0x00000060 0x00000000 0x0000002 0x0>;

			num-ib-windows = <1>;

			#interrupt-cells = <1>;
			interrupt-map-mask = <0x0 0 0 7>;

			interrupt-parent = <&aplic_s>;
			msi-parent = <&imsics_s>;
			interrupts = <15 IRQ_TYPE_EDGE_RISING>, <16 IRQ_TYPE_EDGE_RISING>;
			interrupt-names = "msi", "hp";
			num-lanes = <1>;
			status = "disabled";
		};

		synps_pcie2: pcie_synps@50000000 {
			compatible = "snps,dw-pcie";
			reg = <0x0 0x50000000 0x0 0x8000000>,
			      <0x0 0x6fff0000 0x0 0x0010000>,
			      <0x5f 0xffff0000 0x0 0x0010000>;
			reg-names = "dbi", "config";
			#address-cells = <3>;
			#size-cells = <2>;
			device_type = "pci";
			bus-range = <0x00 0xff>;
			ranges = <0x02000000 0x00000000 0x40000000 0x00000000 0x68000000 0x00000000 0x7ff0000>,
				 <0x03000000 0x00000050 0x00000000 0x00000050 0x00000000 0x000000f 0xffff0000>;

			num-ib-windows = <1>;

			#interrupt-cells = <1>;
			interrupt-map-mask = <0x0 0 0 7>;

			interrupt-parent = <&aplic_s>;
			msi-parent = <&imsics_s>;
			interrupts = <18 IRQ_TYPE_EDGE_RISING>, <19 IRQ_TYPE_EDGE_RISING>;
			interrupt-names = "msi", "hp";
			num-lanes = <1>;
			status = "disabled";
		};

		synps_pcie3: pcie_synps@58000000 {
			compatible = "snps,dw-pcie";
			reg = <0x0 0x58000000 0x0 0x8000000>,
			      <0x0 0x7fff0000 0x0 0x0010000>,
			      <0x7f 0xffff0000 0x0 0x0010000>;
			reg-names = "dbi", "config";
			#address-cells = <3>;
			#size-cells = <2>;
			device_type = "pci";
			bus-range = <0x00 0xff>;
			ranges = <0x02000000 0x00000000 0x40000000 0x00000000 0x78000000 0x00000000 0x7ff0000>,
				 <0x03000000 0x00000070 0x00000000 0x00000070 0x00000000 0x000000f 0xffff0000>;

			num-ib-windows = <1>;

			#interrupt-cells = <1>;
			interrupt-map-mask = <0x0 0 0 7>;

			interrupt-parent = <&aplic_s>;
			msi-parent = <&imsics_s>;
			interrupts = <21 IRQ_TYPE_EDGE_RISING>, <22 IRQ_TYPE_EDGE_RISING>;
			interrupt-names = "msi", "hp";
			num-lanes = <1>;
			status = "disabled";
		};
		xdma_clkc: misc_clk_0 {
			#clock-cells = <0>;
			clock-frequency = <10000000>;
			compatible = "fixed-clock";
		};
		xdma_0: pcie_xdma@48000000 {
			#address-cells = <3>;
			#interrupt-cells = <1>;
			#size-cells = <2>;
			clock-names = "sys_clk", "sys_clk_gt";
			clocks = <&xdma_clkc>, <&xdma_clkc>;
			compatible = "xlnx,xdma-host-3.00", "xlnx,axi-pcie-host-1.00.a";
			device_type = "pci";
			interrupt-map =	<0x0 0 0 1 &pcie_intc_0 1>,
							<0x0 0 0 2 &pcie_intc_0 2>,
							<0x0 0 0 3 &pcie_intc_0 3>,
							<0x0 0 0 4 &pcie_intc_0 4>;
			interrupt-map-mask = <0x0 0 0 7>;
			interrupt-names = "misc", "msi0", "msi1";
			interrupt-parent = <&aplic_s>;
			interrupts = <14 IRQ_TYPE_EDGE_RISING>, <13 IRQ_TYPE_EDGE_RISING>, <12 IRQ_TYPE_EDGE_RISING>;
			msi-parent = <&imsics_s>;
			bus-range = <0x00 0xff>;

			ranges =	 <0x02000000 0x0000000  0x60000000 0x00000000 0x60000000 0x0000000 0x10000000>, // MEM resource Bit32
					 <0x03000000 0x00000040 0x00000000 0x00000040 0x00000000 0x0000020 0x00000000>; // MEM resrouce Bit64 Prefetch
			reg = <0x00000000 0x48000000  0x0 0x8000000>;

			status = "disabled";
			pcie_intc_0: interrupt-controller {
				#address-cells = <0>;
				#interrupt-cells = <1>;
				interrupt-controller ;
			};
		};

		xdma_1: pcie_xdma@50000000 {
			#address-cells = <3>;
			#interrupt-cells = <1>;
			#size-cells = <2>;
			clock-names = "sys_clk", "sys_clk_gt";
			clocks = <&xdma_clkc>, <&xdma_clkc>;
			compatible = "xlnx,xdma-host-3.00", "xlnx,axi-pcie-host-1.00.a";
			device_type = "pci";
			interrupt-map =	<0x0 0 0 1 &pcie_intc_1 1>,
					<0x0 0 0 2 &pcie_intc_1 2>,
					<0x0 0 0 3 &pcie_intc_1 3>,
					<0x0 0 0 4 &pcie_intc_1 4>;
			interrupt-map-mask = <0x0 0 0 7>;
			interrupt-names = "misc", "msi0", "msi1";
			interrupt-parent = <&aplic_s>;
			interrupts = <17 IRQ_TYPE_EDGE_RISING>, <16 IRQ_TYPE_EDGE_RISING>, <15 IRQ_TYPE_EDGE_RISING>;
			msi-parent = <&imsics_s>;
			bus-range = <0x00 0xff>;

			ranges = <0x02000000 0x0000000  0x70000000 0x00000000 0x70000000 0x0000000 0x10000000>, // MEM resource Bit32
				 <0x03000000 0x00000060 0x00000000 0x00000060 0x00000000 0x0000020 0x00000000>; // MEM resrouce Bit64 Prefetch
			reg = <0x00000000 0x50000000  0x0 0x10000000>;

			status = "disabled";
			pcie_intc_1: interrupt-controller {
				#address-cells = <0>;
				#interrupt-cells = <1>;
				interrupt-controller ;
			};
		};

		my_virtio_blk: my_virtio_blk@310a0000 {
			compatible = "virtio,mmio";
			reg = <0 0x310a0000 0 0x1000>;
			interrupt-parent = <&aplic_s>;
			interrupts = <15 IRQ_TYPE_EDGE_RISING>;
			status = "disabled";
		};

		my_virtio_console: my_virtio_console@31080000 {
			compatible = "virtio,mmio";
			reg = <0 0x31080000 0 0x1000>;
			interrupt-parent = <&aplic_s>;
			interrupts = <17 IRQ_TYPE_EDGE_RISING>;
			status = "disabled";
		};
	};

	chosen {
		rng-seed = <0xc8518d39 0x6bde432f 0x4d998c79 0xaa192096 0xdbcf36f3 0x532f3ab3 0x965240fe 0xac379c0e>;
	};

	memory: memory@80000000 {
		device_type = "memory";
		reg = <0x0 0x80000000 0x03 0x40000000>;
	};
};
